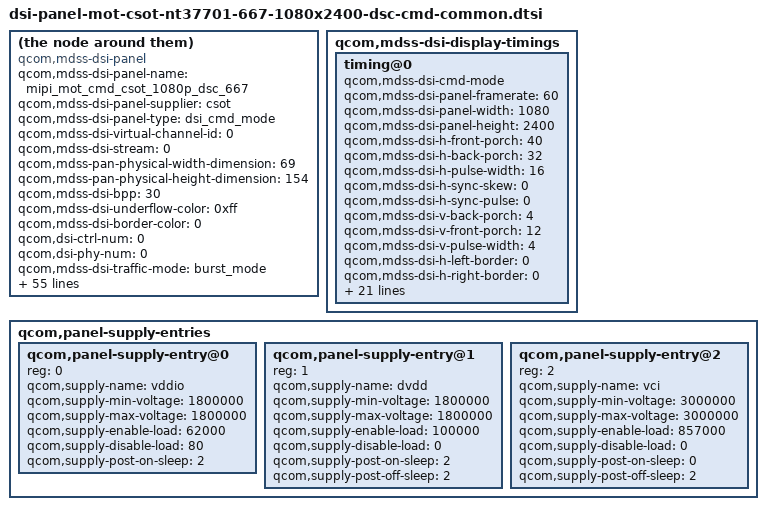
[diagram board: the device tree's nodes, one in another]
/* Copyright (c) 2019-2020, The Linux Foundation. All rights reserved.
 *
 * This program is free software; you can redistribute it and/or modify
 * it under the terms of the GNU General Public License version 2 and
 * only version 2 as published by the Free Software Foundation.
 *
 * This program is distributed in the hope that it will be useful,
 * but WITHOUT ANY WARRANTY; without even the implied warranty of
 * MERCHANTABILITY or FITNESS FOR A PARTICULAR PURPOSE.  See the
 * GNU General Public License for more details.
 */

compatible = "qcom,mdss-dsi-panel";
qcom,mdss-dsi-panel-name = "mipi_mot_cmd_csot_1080p_dsc_667";
qcom,mdss-dsi-panel-supplier = "csot";
qcom,mdss-dsi-panel-type = "dsi_cmd_mode";
qcom,mdss-dsi-virtual-channel-id = <0>;
qcom,mdss-dsi-stream = <0>;
qcom,mdss-pan-physical-width-dimension = <69>;
qcom,mdss-pan-physical-height-dimension = <154>;
qcom,mdss-dsi-bpp = <30>;
qcom,mdss-dsi-underflow-color = <0xff>;
qcom,mdss-dsi-border-color = <0>;

qcom,dsi-ctrl-num = <0>;
qcom,dsi-phy-num = <0>;

qcom,mdss-dsi-traffic-mode = "burst_mode";
qcom,mdss-dsi-bllp-eof-power-mode;
qcom,mdss-dsi-bllp-power-mode;
qcom,mdss-dsi-lane-0-state;
qcom,mdss-dsi-lane-1-state;
qcom,mdss-dsi-lane-2-state;
qcom,mdss-dsi-lane-3-state;

qcom,mdss-dsi-dma-trigger = "trigger_sw";
qcom,mdss-dsi-mdp-trigger = "none";
qcom,mdss-dsi-reset-sequence = <0 11>, <1 1>, <0 1>, <1 11>;
qcom,mdss-dsi-lp11-init;
qcom,mdss-dsi-tx-eot-append;
qcom,mdss-dsi-te-pin-select = <1>;
qcom,mdss-dsi-te-dcs-command = <1>;

qcom,mdss-dsi-te-using-te-pin;

//qcom,esd-check-enabled;
qcom,mdss-dsi-panel-status-check-mode = "te_chk_reg_rd";
qcom,mdss-dsi-panel-status-command = [06 01 00 01 00 00 01 0a];
qcom,mdss-dsi-panel-status-command-state = "dsi_lp_mode";
qcom,mdss-dsi-panel-status-value = <0x9c>;
qcom,mdss-dsi-panel-status-read-length = <1>;
//qcom,mdss-dsi-no-panel-on-read-support;

qcom,bklt-dcs-2bytes-enabled;
qcom,mdss-dsi-bl-min-level = <3>;
qcom,mdss-dsi-bl-max-level = <2047>;
qcom,mdss-dsi-bl-default-level = <1024>;
qcom,mdss-brightness-max-level = <2047>;
qcom,mdss-dsi-bl-pmic-control-type = "bl_ctrl_dcs";

qcom,mdss-dsi-hbm-on-command = [
		39 01 00 00 00 00 03 51 0F FF];
qcom,mdss-dsi-hbm-on-command-state = "dsi_lp_mode";
qcom,mdss-dsi-hbm-off-command = [
		39 01 00 00 00 00 03 51 07 FF];
qcom,mdss-dsi-hbm-off-command-state = "dsi_lp_mode";

qcom,mdss-dsi-color-vbt-command = [
                15 01 00 00 00 00 02 55 90];
qcom,mdss-dsi-color-vbt-command-state = "dsi_lp_mode";
qcom,mdss-dsi-color-std-command = [
                15 01 00 00 00 00 02 55 90];
qcom,mdss-dsi-color-std-command-state = "dsi_lp_mode";
qcom,mdss-dsi-color-game-command = [
		15 01 00 00 00 00 02 55 80];
qcom,mdss-dsi-color-game-command-state = "dsi_lp_mode";
qcom,mdss-dsi-color-none-command = [
		15 01 00 00 00 00 02 55 90];
qcom,mdss-dsi-color-none-command-state = "dsi_lp_mode";

//qcom,mdss-dsi-acl-on-command = [
//		39 01 00 00 00 00 06 F0 55 AA 52 08 00
//		15 00 00 00 00 00 02 B0 0C
//		15 01 00 00 00 00 02 55 05];
//qcom,mdss-dsi-acl-off-command = [
//		15 01 00 00 00 00 02 55 00];

qcom,mdss-dsi-panel-hbm-is-51cmd;

qcom,mdss-dsi-display-timings {
	timing@0{
		/* 60 FPS */
		qcom,mdss-dsi-cmd-mode;
		qcom,mdss-dsi-panel-framerate = <60>;
		qcom,mdss-dsi-panel-width = <1080>;
		qcom,mdss-dsi-panel-height = <2400>;
		qcom,mdss-dsi-h-front-porch = <40>;
		qcom,mdss-dsi-h-back-porch = <32>;
		qcom,mdss-dsi-h-pulse-width = <16>;
		qcom,mdss-dsi-h-sync-skew = <0>;
		qcom,mdss-dsi-h-sync-pulse = <0>;
		qcom,mdss-dsi-v-back-porch = <4>;
		qcom,mdss-dsi-v-front-porch = <12>;
		qcom,mdss-dsi-v-pulse-width = <4>;
		qcom,mdss-dsi-h-left-border = <0>;
		qcom,mdss-dsi-h-right-border = <0>;
		qcom,mdss-dsi-v-top-border = <0>;
		qcom,mdss-dsi-v-bottom-border = <0>;
		qcom,mdss-dsi-panel-jitter = <0x20 0xa>;
		//qcom,mdss-mdp-transfer-time-us = <15790>;
		//qcom,mdss-dsi-panel-clockrate = <458250000>;
		qcom,mdss-dsi-timing-switch-command = [
			15 01 00 00 00 00 02 2F 01
		];
		qcom,mdss-dsi-on-command = [
			39 01 00 00 00 00 06 F0 55 AA 52 08 00
			39 01 00 00 00 00 02 6F 02
			39 01 00 00 00 00 03 EC 81 C2
			39 01 00 00 00 00 06 F0 55 AA 52 08 00
			39 01 00 00 00 00 19 CC 40 54 5A 60 66 6A 6C 6C 68 62 5B 53 4D 48 44 41 40 50 60 70 58 68 74 74
			39 01 00 00 00 00 12 CD 40 40 40 40 40 40 40 40 40 45 49 4C 4B 48 44 41 40
			39 01 00 00 00 00 13 CE 00 40 40 40 40 40 40 40 40 40 40 40 40 40 40 40 40 40
			39 01 00 00 00 00 12 CF 40 40 40 40 40 40 40 40 40 40 40 40 40 40 40 40 40
			39 01 00 00 00 00 07 D0 00 00 FC 74 0C 1D
			39 01 00 00 00 00 2E D1 50 50 50 50 50 50 50 50 50 50 50 50 50 50 50 50 50 50 50 50 50 50 50 50 00 00 00 00 00 00 00 00 00 00 00 00 00 06 0C 03 09 0F 68 88 00
			39 01 00 00 00 00 07 D3 30 52 74 74 50 10
			39 01 00 00 00 00 1A D4 0F 77 74 0F 00 14 0F 18 1F 05 0D 14 03 07 0A A0 75 FA 10 44 12 00 00 80 00
			39 01 00 00 00 00 14 D7 30 40 40 40 40 40 40 40 40 40 40 40 40 40 40 40 40 40 40
			39 01 00 00 00 00 02 55 90
			39 01 00 00 00 00 06 F0 55 AA 52 08 07
			39 01 00 00 00 00 03 c0 01 0f
			39 01 00 00 00 00 06 F0 55 AA 52 08 01
			39 01 00 00 00 00 02 6f 01
			39 01 00 00 00 00 02 cd 81
			39 01 00 00 00 00 06 F0 55 AA 52 08 08
			39 01 00 00 00 00 03 C0 0F 7E
			39 01 00 00 00 00 06 F0 55 AA 52 08 00
			15 01 00 00 00 00 02 6F 06
			39 01 00 00 00 00 04 B5 4E 1F 50
			15 01 00 00 00 00 02 6F 0D
			15 01 00 00 00 00 02 B5 50
			15 01 00 00 00 00 02 6F 10
			39 01 00 00 00 00 06 B5 1F 1F 1F 1F 1F
			15 01 00 00 00 00 02 03 01
			15 01 00 00 00 00 02 90 01
			39 01 00 00 00 00 13 91 AB 28 00 0C C2 00 03 1C 01 7E 00 0F 08 BB 04 3D 10 F0
			15 01 00 00 00 00 02 2C 00
			39 01 00 00 00 00 03 51 00 00
			15 01 00 00 00 00 02 53 20
			15 01 00 00 00 00 02 35 00
			39 01 00 00 00 00 05 2A 00 00 04 37
			39 01 00 00 00 00 05 2B 00 00 09 5F
			15 01 00 00 00 00 02 2F 01
			05 01 00 00 78 00 01 11
			05 01 00 00 00 00 01 29];	/* display on */
		qcom,mdss-dsi-off-command = [
			05 01 00 00 00 00 01 28		/* display_off */
			05 01 00 00 78 00 01 10];	/* enter sleep mode */

		qcom,mdss-dsi-on-command-state = "dsi_lp_mode";
		qcom,mdss-dsi-off-command-state = "dsi_lp_mode";
		qcom,mdss-dsi-timing-switch-command-state = "dsi_lp_mode";

		qcom,compression-mode = "dsc";
		qcom,mdss-dsc-version = <0x11>;
		qcom,mdss-dsc-slice-height = <12>;
		qcom,mdss-dsc-slice-width = <1080>;
		qcom,mdss-dsc-slice-per-pkt = <1>;
		qcom,mdss-dsc-bit-per-component = <10>;
		qcom,mdss-dsc-bit-per-pixel = <10>;
		qcom,mdss-dsc-block-prediction-enable;
	};
};

qcom,panel-supply-entries {
	#address-cells = <1>;
	#size-cells = <0>;

	qcom,panel-supply-entry@0 {
		reg = <0>;
		qcom,supply-name = "vddio";
		qcom,supply-min-voltage = <1800000>;
		qcom,supply-max-voltage = <1800000>;
		qcom,supply-enable-load = <62000>;
		qcom,supply-disable-load = <80>;
		qcom,supply-post-on-sleep = <2>;
	};

	qcom,panel-supply-entry@1 {
		reg = <1>;
		qcom,supply-name = "dvdd";
		qcom,supply-min-voltage = <1800000>;
		qcom,supply-max-voltage = <1800000>;
		qcom,supply-enable-load = <100000>;
		qcom,supply-disable-load = <0>;
		qcom,supply-post-on-sleep = <2>;
		qcom,supply-post-off-sleep = <2>;
	};

	qcom,panel-supply-entry@2 {
		reg = <2>;
		qcom,supply-name = "vci";
		qcom,supply-min-voltage = <3000000>;
		qcom,supply-max-voltage = <3000000>;
		qcom,supply-enable-load = <857000>;
		qcom,supply-disable-load = <0>;
		qcom,supply-post-on-sleep = <0>;
		qcom,supply-post-off-sleep = <2>;
	};
};
